VERSION ""

NS_ :

BS_:

BU_: ELC ZGW

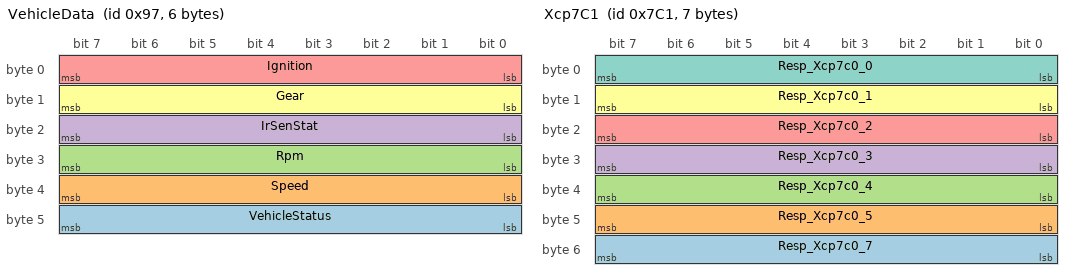
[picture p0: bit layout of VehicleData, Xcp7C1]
BO_ 151 VehicleData: 6 ZGW
 SG_ VehicleStatus : 40|8@1+ (1,0) [0|255] ""  ELC
 SG_ Speed : 32|8@1+ (1,0) [0|0] ""  ELC
 SG_ Rpm : 24|8@1+ (1,0) [0|255] ""  ELC
 SG_ IrSenStat : 16|8@1+ (1,0) [0|255] ""  ELC
 SG_ Ignition : 0|8@1+ (1,0) [0|255] ""  ELC
 SG_ Gear : 8|8@1+ (1,0) [0|255] ""  ELC

BO_ 1985 Xcp7C1: 7 ELC
 SG_ Resp_Xcp7c0_7 : 48|8@1+ (1,0) [0|255] ""  ZGW
 SG_ Resp_Xcp7c0_5 : 40|8@1+ (1,0) [0|255] ""  ZGW
 SG_ Resp_Xcp7c0_4 : 32|8@1+ (1,0) [0|255] ""  ZGW
 SG_ Resp_Xcp7c0_3 : 24|8@1+ (1,0) [0|255] ""  ZGW
 SG_ Resp_Xcp7c0_2 : 16|8@1+ (1,0) [0|255] ""  ZGW
 SG_ Resp_Xcp7c0_1 : 8|8@1+ (1,0) [0|255] ""  ZGW
 SG_ Resp_Xcp7c0_0 : 0|8@1+ (1,0) [0|255] ""  ZGW

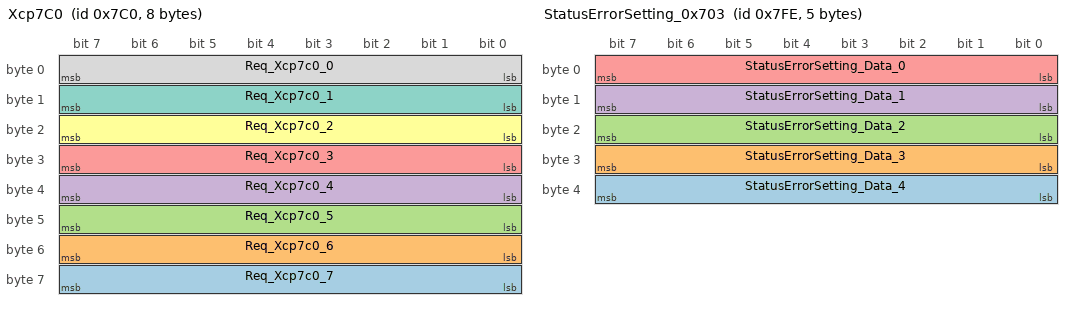
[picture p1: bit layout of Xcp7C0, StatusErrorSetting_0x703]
BO_ 1984 Xcp7C0: 8 ELC
 SG_ Req_Xcp7c0_7 : 56|8@1+ (1,0) [0|255] ""  ELC
 SG_ Req_Xcp7c0_6 : 48|8@1+ (1,0) [0|255] ""  ELC
 SG_ Req_Xcp7c0_5 : 40|8@1+ (1,0) [0|255] ""  ELC
 SG_ Req_Xcp7c0_4 : 32|8@1+ (1,0) [0|255] ""  ELC
 SG_ Req_Xcp7c0_3 : 24|8@1+ (1,0) [0|255] ""  ELC
 SG_ Req_Xcp7c0_2 : 16|8@1+ (1,0) [0|255] ""  ELC
 SG_ Req_Xcp7c0_1 : 8|8@1+ (1,0) [0|255] ""  ELC
 SG_ Req_Xcp7c0_0 : 0|8@1+ (1,0) [0|255] ""  ELC

BO_ 1773 CurrentSense_L1: 4 ELC
 SG_ CurrentSense_L1_Float : 0|32@1- (1,0) [-3.4E+38|3.4E+38] ""  ZGW

BO_ 1774 TempMeas: 8 ELC
 SG_ McuTemperature : 32|32@1- (1,0) [-3.4E+38|3.4E+38] ""  ZGW
 SG_ NTCTemperature_L1 : 0|32@1- (1,0) [-3.4E+38|3.4E+38] ""  ZGW

BO_ 2046 StatusErrorSetting_0x703: 5 ELC
 SG_ StatusErrorSetting_Data_4 : 32|8@1+ (1,0) [0|255] ""  ZGW
 SG_ StatusErrorSetting_Data_3 : 24|8@1+ (1,0) [0|255] ""  ZGW
 SG_ StatusErrorSetting_Data_2 : 16|8@1+ (1,0) [0|255] ""  ZGW
 SG_ StatusErrorSetting_Data_1 : 8|8@1+ (1,0) [0|255] ""  ZGW
 SG_ StatusErrorSetting_Data_0 : 0|8@1+ (1,0) [0|255] ""  ZGW

BO_ 1023 Networkmanagement3_Status: 1 ZGW
 SG_ NM3S_PN1 : 0|8@1+ (1,0) [0|255] ""  ELC

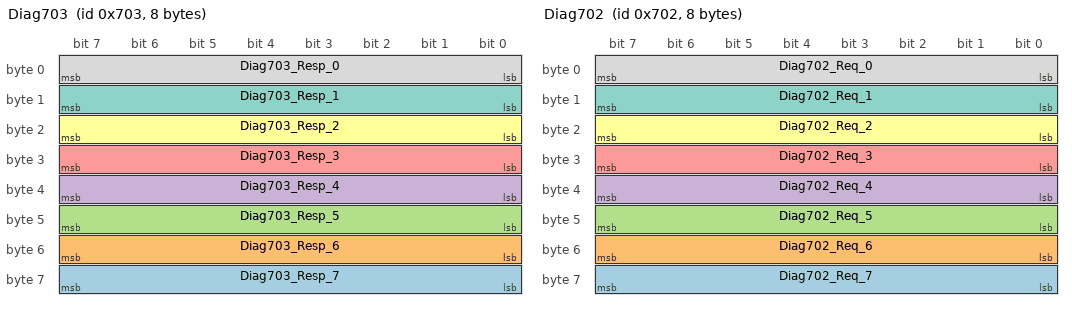
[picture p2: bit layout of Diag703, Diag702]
BO_ 1795 Diag703: 8 ZGW
 SG_ Diag703_Resp_7 : 56|8@1+ (1,0) [0|255] ""  ZGW
 SG_ Diag703_Resp_6 : 48|8@1+ (1,0) [0|255] ""  ZGW
 SG_ Diag703_Resp_5 : 40|8@1+ (1,0) [0|255] ""  ZGW
 SG_ Diag703_Resp_4 : 32|8@1+ (1,0) [0|255] ""  ZGW
 SG_ Diag703_Resp_3 : 24|8@1+ (1,0) [0|255] ""  ZGW
 SG_ Diag703_Resp_2 : 16|8@1+ (1,0) [0|255] ""  ZGW
 SG_ Diag703_Resp_1 : 8|8@1+ (1,0) [0|255] ""  ZGW
 SG_ Diag703_Resp_0 : 0|8@1+ (1,0) [0|255] ""  ZGW

BO_ 1794 Diag702: 8 ZGW
 SG_ Diag702_Req_7 : 56|8@1+ (1,0) [0|255] ""  ELC
 SG_ Diag702_Req_6 : 48|8@1+ (1,0) [0|255] ""  ELC
 SG_ Diag702_Req_5 : 40|8@1+ (1,0) [0|255] ""  ELC
 SG_ Diag702_Req_4 : 32|8@1+ (1,0) [0|255] ""  ELC
 SG_ Diag702_Req_3 : 24|8@1+ (1,0) [0|255] ""  ELC
 SG_ Diag702_Req_2 : 16|8@1+ (1,0) [0|255] ""  ELC
 SG_ Diag702_Req_1 : 8|8@1+ (1,0) [0|255] ""  ELC
 SG_ Diag702_Req_0 : 0|8@1+ (1,0) [0|255] ""  ELC

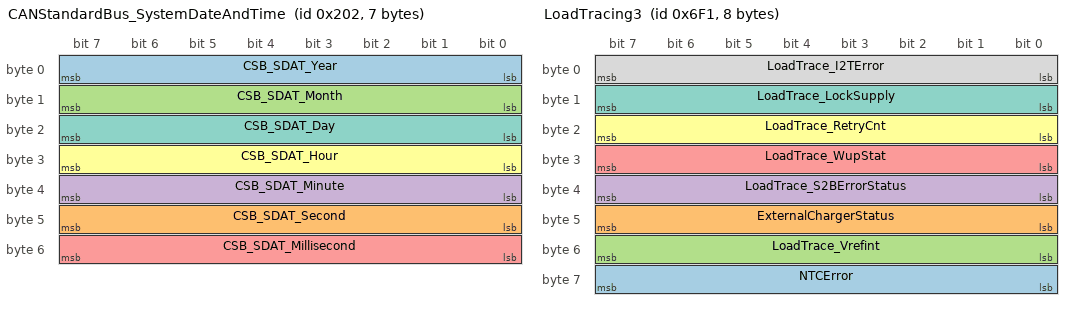
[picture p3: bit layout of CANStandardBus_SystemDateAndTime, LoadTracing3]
BO_ 514 CANStandardBus_SystemDateAndTime: 7 ZGW
 SG_ CSB_SDAT_Year : 0|8@1+ (1,0) [0|255] ""  ELC
 SG_ CSB_SDAT_Second : 40|8@1+ (1,0) [0|255] ""  ELC
 SG_ CSB_SDAT_Month : 8|8@1+ (1,0) [0|255] ""  ELC
 SG_ CSB_SDAT_Minute : 32|8@1+ (1,0) [0|255] ""  ELC
 SG_ CSB_SDAT_Millisecond : 48|8@1+ (1,0) [0|255] ""  ELC
 SG_ CSB_SDAT_Hour : 24|8@1+ (1,0) [0|255] ""  ELC
 SG_ CSB_SDAT_Day : 16|8@1+ (1,0) [0|255] ""  ELC

BO_ 1777 LoadTracing3: 8 ELC
 SG_ NTCError : 56|8@1+ (1,0) [0|255] "" Vector__XXX
 SG_ ExternalChargerStatus : 40|8@1+ (1,0) [0|255] "" Vector__XXX
 SG_ LoadTrace_Vrefint : 48|8@1+ (1,0) [0|255] "" Vector__XXX
 SG_ LoadTrace_S2BErrorStatus : 32|8@1+ (1,0) [0|255] "" Vector__XXX
 SG_ LoadTrace_WupStat : 24|8@1+ (1,0) [0|255] ""  ZGW
 SG_ LoadTrace_RetryCnt : 16|8@1+ (1,0) [0|255] ""  ZGW
 SG_ LoadTrace_LockSupply : 8|8@1+ (1,0) [0|255] ""  ZGW
 SG_ LoadTrace_I2TError : 0|8@1+ (1,0) [0|255] ""  ZGW

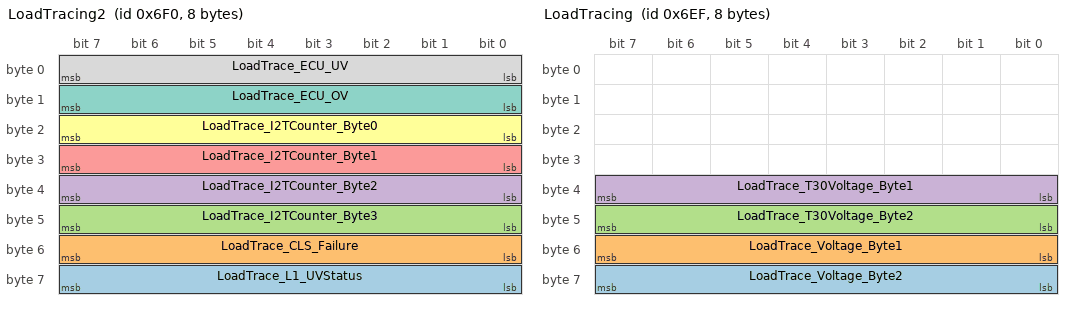
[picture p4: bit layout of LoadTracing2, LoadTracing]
BO_ 1776 LoadTracing2: 8 ELC
 SG_ LoadTrace_L1_UVStatus : 56|8@1+ (1,0) [0|255] ""  ZGW
 SG_ LoadTrace_CLS_Failure : 48|8@1+ (1,0) [0|255] ""  ZGW
 SG_ LoadTrace_I2TCounter_Byte3 : 40|8@1+ (1,0) [0|255] ""  ZGW
 SG_ LoadTrace_I2TCounter_Byte2 : 32|8@1+ (1,0) [0|255] ""  ZGW
 SG_ LoadTrace_I2TCounter_Byte1 : 24|8@1+ (1,0) [0|255] ""  ZGW
 SG_ LoadTrace_I2TCounter_Byte0 : 16|8@1+ (1,0) [0|255] ""  ZGW
 SG_ LoadTrace_ECU_OV : 8|8@1+ (1,0) [0|255] ""  ZGW
 SG_ LoadTrace_ECU_UV : 0|8@1+ (1,0) [0|255] ""  ZGW

BO_ 1775 LoadTracing: 8 ELC
 SG_ LoadTrace_Voltage_Byte2 : 56|8@1+ (1,0) [0|255] ""  ZGW
 SG_ LoadTrace_Voltage_Byte1 : 48|8@1+ (1,0) [0|255] ""  ZGW
 SG_ LoadTrace_T30Voltage_Byte2 : 40|8@1+ (1,0) [0|255] ""  ZGW
 SG_ LoadTrace_T30Voltage_Byte1 : 32|8@1+ (1,0) [0|255] ""  ZGW

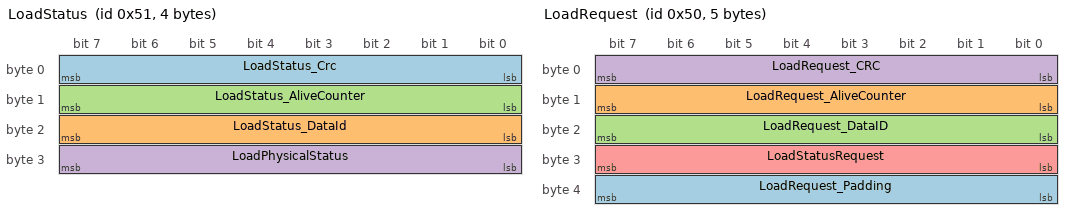
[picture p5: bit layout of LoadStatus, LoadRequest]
BO_ 81 LoadStatus: 4 ELC
 SG_ LoadStatus_Crc : 0|8@1+ (1,0) [0|255] "" Vector__XXX
 SG_ LoadStatus_DataId : 16|8@1+ (1,0) [0|255] "" Vector__XXX
 SG_ LoadStatus_AliveCounter : 8|8@1+ (1,0) [0|15] "" Vector__XXX
 SG_ LoadPhysicalStatus : 24|8@1+ (1,0) [0|255] ""  ZGW

BO_ 80 LoadRequest: 5 ZGW
 SG_ LoadRequest_Padding : 32|8@1+ (1,0) [0|255] "" Vector__XXX
 SG_ LoadRequest_AliveCounter : 8|8@1+ (1,0) [0|15] "" Vector__XXX
 SG_ LoadRequest_DataID : 16|8@1+ (1,0) [0|255] "" Vector__XXX
 SG_ LoadRequest_CRC : 0|8@1+ (1,0) [0|255] "" Vector__XXX
 SG_ LoadStatusRequest : 24|8@1+ (1,0) [0|255] ""  ELC

BA_DEF_  "BusType" STRING ;
BA_DEF_DEF_  "BusType" "CAN";
SIG_VALTYPE_ 1773 CurrentSense_L1_Float : 1;
SIG_VALTYPE_ 1774 McuTemperature : 1;
SIG_VALTYPE_ 1774 NTCTemperature_L1 : 1;
